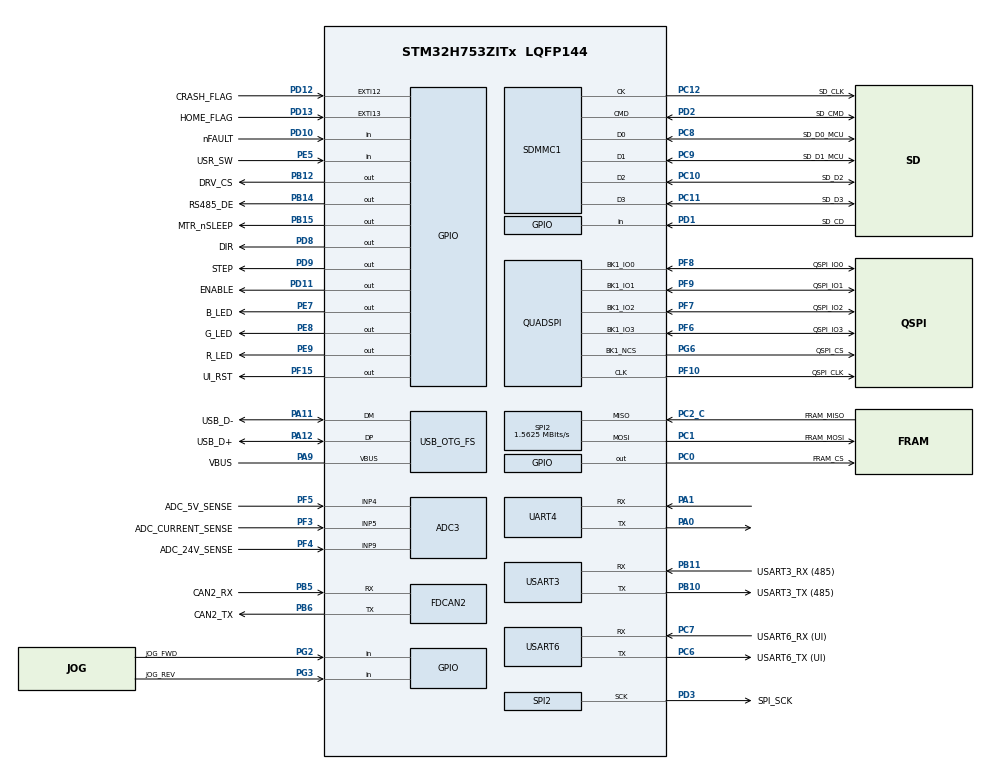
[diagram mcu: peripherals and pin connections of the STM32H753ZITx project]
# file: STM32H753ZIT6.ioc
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ADC3.Channel-0\#ChannelRegularConversion=ADC_CHANNEL_5
ADC3.Channel-1\#ChannelRegularConversion=ADC_CHANNEL_9
ADC3.Channel-2\#ChannelRegularConversion=ADC_CHANNEL_4
ADC3.NbrOfConversion=3
ADC3.NbrOfConversionFlag=1
ADC3.OffsetNumber-0\#ChannelRegularConversion=ADC_OFFSET_NONE
ADC3.OffsetNumber-1\#ChannelRegularConversion=ADC_OFFSET_NONE
ADC3.OffsetNumber-2\#ChannelRegularConversion=ADC_OFFSET_NONE
ADC3.OffsetSignedSaturation-0\#ChannelRegularConversion=DISABLE
ADC3.OffsetSignedSaturation-1\#ChannelRegularConversion=DISABLE
ADC3.OffsetSignedSaturation-2\#ChannelRegularConversion=DISABLE
ADC3.Rank-0\#ChannelRegularConversion=1
ADC3.Rank-1\#ChannelRegularConversion=2
ADC3.Rank-2\#ChannelRegularConversion=3
ADC3.SamplingTime-0\#ChannelRegularConversion=ADC_SAMPLETIME_810CYCLES_5
ADC3.SamplingTime-1\#ChannelRegularConversion=ADC_SAMPLETIME_810CYCLES_5
ADC3.SamplingTime-2\#ChannelRegularConversion=ADC_SAMPLETIME_810CYCLES_5
CORTEX_M7.default_mode_Activation=1
FDCAN2.AutoRetransmission=ENABLE
FDCAN2.CalculateBaudRateNominal=500000
FDCAN2.CalculateTimeBitNominal=2000
FDCAN2.CalculateTimeQuantumNominal=100.0
FDCAN2.NominalPrescaler=5
FDCAN2.NominalTimeSeg1=15
FDCAN2.NominalTimeSeg2=4
FDCAN2.RxFifo0ElmtsNbr=3
FDCAN2.StdFiltersNbr=1
FDCAN2.TxEventsNbr=3
FDCAN2.TxFifoQueueElmtsNbr=3
Mcu.Family=STM32H7
Mcu.Name=STM32H753ZITx
Mcu.Package=LQFP144
NVIC.EXTI15_10_IRQn=true\:6\:0\:true\:false\:true\:true\:true\:true
NVIC.OTG_FS_IRQn=true\:5\:0\:true\:false\:true\:true\:true\:true
NVIC.PriorityGroup=NVIC_PRIORITYGROUP_4
PA0.Mode=Asynchronous
PA0.Signal=UART4_TX
PA1.Mode=Asynchronous
PA1.Signal=UART4_RX
PA11.GPIO_Label=USB_D-
PA11.Mode=Device_Only
PA11.Signal=USB_OTG_FS_DM
PA12.GPIO_Label=USB_D+
PA12.Mode=Device_Only
PA12.Signal=USB_OTG_FS_DP
PA13\ (JTMS/SWDIO).GPIO_Label=DBG_SWDIO
PA13\ (JTMS/SWDIO).Mode=Serial_Wire
PA13\ (JTMS/SWDIO).Signal=DEBUG_JTMS-SWDIO
PA14\ (JTCK/SWCLK).GPIO_Label=DBG_SWCLK
PA14\ (JTCK/SWCLK).Mode=Serial_Wire
PA14\ (JTCK/SWCLK).Signal=DEBUG_JTCK-SWCLK
PA9.GPIO_Label=VBUS
PA9.Mode=Activate_VBUS
PA9.Signal=USB_OTG_FS_VBUS
PB10.GPIO_Label=USART3_TX (485)
PB10.Mode=Asynchronous
PB10.Signal=USART3_TX
PB11.GPIO_Label=USART3_RX (485)
PB11.Mode=Asynchronous
PB11.Signal=USART3_RX
PB12.GPIO_Label=DRV_CS
PB12.PinState=GPIO_PIN_SET
PB12.Signal=GPIO_Output
PB14.GPIO_Label=RS485_DE
PB14.Signal=GPIO_Output
PB15.GPIO_Label=MTR_nSLEEP
PB15.Signal=GPIO_Output
PB3\ (JTDO/TRACESWO).GPIO_Label=DBG_SWO
PB3\ (JTDO/TRACESWO).Signal=DEBUG_JTDO-SWO
PB5.GPIO_Label=CAN2_RX
PB5.Mode=FDCAN_Activate
PB5.Signal=FDCAN2_RX
PB6.GPIO_Label=CAN2_TX
PB6.Mode=FDCAN_Activate
PB6.Signal=FDCAN2_TX
PC0.GPIO_Label=FRAM_CS
PC0.PinState=GPIO_PIN_SET
PC0.Signal=GPIO_Output
PC1.GPIO_Label=FRAM_MOSI
PC1.Mode=Full_Duplex_Master
PC1.Signal=SPI2_MOSI
PC10.GPIO_Label=SD_D2
PC10.Mode=SD_4_bits_Wide_bus
PC10.Signal=SDMMC1_D2
PC11.GPIO_Label=SD_D3
PC11.Mode=SD_4_bits_Wide_bus
PC11.Signal=SDMMC1_D3
PC12.GPIO_Label=SD_CLK
PC12.Mode=SD_4_bits_Wide_bus
PC12.Signal=SDMMC1_CK
PC2_C.GPIO_Label=FRAM_MISO
PC2_C.Mode=Full_Duplex_Master
PC2_C.Signal=SPI2_MISO
PC6.GPIO_Label=USART6_TX (UI)
PC6.Mode=Asynchronous
PC6.Signal=USART6_TX
PC7.GPIO_Label=USART6_RX (UI)
PC7.Mode=Asynchronous
PC7.Signal=USART6_RX
PC8.GPIO_Label=SD_D0_MCU
PC8.Mode=SD_4_bits_Wide_bus
PC8.Signal=SDMMC1_D0
PC9.GPIO_Label=SD_D1_MCU
PC9.Mode=SD_4_bits_Wide_bus
PC9.Signal=SDMMC1_D1
PD1.GPIO_Label=SD_CD
PD1.GPIO_PuPd=GPIO_PULLUP
PD1.Signal=GPIO_Input
PD10.GPIO_Label=nFAULT
PD10.GPIO_PuPd=GPIO_PULLUP
PD10.Signal=GPIO_Input
PD11.GPIO_Label=ENABLE
PD11.GPIO_Speed=GPIO_SPEED_FREQ_LOW
PD11.PinState=GPIO_PIN_RESET
PD11.Signal=GPIO_Output
PD12.GPIO_Label=CRASH_FLAG
PD12.GPIO_ModeDefaultEXTI=GPIO_MODE_IT_FALLING
PD12.GPIO_PuPd=GPIO_PULLUP
PD12.Signal=GPXTI12
PD13.GPIO_Label=HOME_FLAG
PD13.GPIO_ModeDefaultEXTI=GPIO_MODE_IT_FALLING
PD13.GPIO_PuPd=GPIO_PULLUP
PD13.Signal=GPXTI13
PD2.GPIO_Label=SD_CMD
PD2.Mode=SD_4_bits_Wide_bus
PD2.Signal=SDMMC1_CMD
PD3.GPIO_Label=SPI_SCK
PD3.Mode=Full_Duplex_Master
PD3.Signal=SPI2_SCK
PD8.GPIO_Label=DIR
PD8.Signal=GPIO_Output
PD9.GPIO_Label=STEP
PD9.Signal=GPIO_Output
PE5.GPIO_Label=USR_SW
PE5.GPIO_PuPd=GPIO_PULLUP
PE5.Signal=GPIO_Input
PE7.GPIO_Label=B_LED
PE7.Signal=GPIO_Output
PE8.GPIO_Label=G_LED
PE8.Signal=GPIO_Output
PE9.GPIO_Label=R_LED
PE9.Signal=GPIO_Output
PF10.GPIO_Label=QSPI_CLK
PF10.Mode=Single Bank 1
PF10.Signal=QUADSPI_CLK
PF15.GPIO_Label=UI_RST
PF15.Signal=GPIO_Output
PF3.GPIO_Label=ADC_CURRENT_SENSE
PF3.Mode=IN5-Single-Ended
PF3.Signal=ADC3_INP5
PF4.GPIO_Label=ADC_24V_SENSE
PF4.Mode=IN9-Single-Ended
PF4.Signal=ADC3_INP9
PF5.GPIO_Label=ADC_5V_SENSE
PF5.Mode=IN4-Single-Ended
PF5.Signal=ADC3_INP4
PF6.GPIO_Label=QSPI_IO3
PF6.Mode=Single Bank 1
PF6.Signal=QUADSPI_BK1_IO3
PF7.GPIO_Label=QSPI_IO2
PF7.Mode=Single Bank 1
PF7.Signal=QUADSPI_BK1_IO2
PF8.GPIO_Label=QSPI_IO0
PF8.Mode=Single Bank 1
PF8.Signal=QUADSPI_BK1_IO0
PF9.GPIO_Label=QSPI_IO1
PF9.Mode=Single Bank 1
PF9.Signal=QUADSPI_BK1_IO1
PG2.GPIO_Label=JOG_FWD
PG2.GPIO_PuPd=GPIO_PULLUP
PG2.Signal=GPIO_Input
PG3.GPIO_Label=JOG_REV
PG3.GPIO_PuPd=GPIO_PULLUP
PG3.Signal=GPIO_Input
PG6.GPIO_Label=QSPI_CS
PG6.Mode=Single Bank 1
PG6.Signal=QUADSPI_BK1_NCS
PH0-OSC_IN\ (PH0).GPIO_Label=HSE_IN
PH0-OSC_IN\ (PH0).Mode=HSE-External-Oscillator
PH0-OSC_IN\ (PH0).Signal=RCC_OSC_IN
PH1-OSC_OUT\ (PH1).GPIO_Label=HSE_OUT
PH1-OSC_OUT\ (PH1).Mode=HSE-External-Oscillator
PH1-OSC_OUT\ (PH1).Signal=RCC_OSC_OUT
ProjectManager.HeapSize=0x200
ProjectManager.StackSize=0x400
ProjectManager.TargetToolchain=STM32CubeIDE
RCC.ADCFreq_Value=75000000
RCC.APB1Freq_Value=32000000
RCC.APB2Freq_Value=32000000
RCC.APB3Freq_Value=64000000
RCC.APB4Freq_Value=64000000
RCC.CortexFreq_Value=64000000
RCC.D2PPRE1=RCC_APB1_DIV2
RCC.D2PPRE2=RCC_APB2_DIV2
RCC.DIVM1=2
RCC.DIVM2=2
RCC.DIVN1=12
RCC.DIVN2=12
RCC.DIVQ1=3
RCC.HCLKFreq_Value=64000000
RCC.PLL2FRACN=0
RCC.PLL3FRACN=0
RCC.PLLFRACN=0
RCC.SYSCLKFreq_VALUE=64000000
RCC.USBFreq_Value=50000000
SPI2.BaudRatePrescaler=SPI_BAUDRATEPRESCALER_32
SPI2.CalculateBaudRate=1.5625 MBits/s
SPI2.DataSize=SPI_DATASIZE_8BIT
SPI2.Direction=SPI_DIRECTION_2LINES
SPI2.Mode=SPI_MODE_MASTER
SPI2.VirtualType=VM_MASTER
USART3.VirtualMode-Asynchronous=VM_ASYNC
USART6.VirtualMode-Asynchronous=VM_ASYNC
USB_OTG_FS.VirtualMode=Device_Only
VP_MEMORYMAP_VS_MEMORYMAP.Mode=CurAppReg
board=custom

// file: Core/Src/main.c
/* USER CODE BEGIN Header */
/**
  ******************************************************************************
  * @file           : main.c
  * @brief          : Main program body
  ******************************************************************************
  * @attention
  *
  * Copyright (c) 2026 STMicroelectronics.
  * All rights reserved.
  *
  * This software is licensed under terms that can be found in the LICENSE file
  * in the root directory of this software component.
  * If no LICENSE file comes with this software, it is provided AS-IS.
  *
  ******************************************************************************
  */
/* USER CODE END Header */
#include "main.h"

ADC_HandleTypeDef hadc3;

FDCAN_HandleTypeDef hfdcan2;

QSPI_HandleTypeDef hqspi;

SD_HandleTypeDef hsd1;

SPI_HandleTypeDef hspi2;

UART_HandleTypeDef huart4;
UART_HandleTypeDef huart3;
UART_HandleTypeDef huart6;

PCD_HandleTypeDef hpcd_USB_OTG_FS;

void SystemClock_Config(void);
static void MPU_Config(void);
static void MX_GPIO_Init(void);
static void MX_UART4_Init(void);
static void MX_FDCAN2_Init(void);
static void MX_QUADSPI_Init(void);
static void MX_SDMMC1_SD_Init(void);
static void MX_SPI2_Init(void);
static void MX_USART3_UART_Init(void);
static void MX_USB_OTG_FS_PCD_Init(void);
static void MX_ADC3_Init(void);
static void MX_USART6_UART_Init(void);

int main(void)
{

  /* MPU Configuration--------------------------------------------------------*/
  MPU_Config();

  /* MCU Configuration--------------------------------------------------------*/

  /* Reset of all peripherals, Initializes the Flash interface and the Systick. */
  HAL_Init();

  /* Configure the system clock */
  SystemClock_Config();

  /* Initialize all configured peripherals */
  MX_GPIO_Init();
  MX_UART4_Init();
  MX_FDCAN2_Init();
  MX_QUADSPI_Init();
  MX_SDMMC1_SD_Init();
  MX_SPI2_Init();
  MX_USART3_UART_Init();
  MX_USB_OTG_FS_PCD_Init();
  MX_ADC3_Init();
  MX_USART6_UART_Init();
  /* USER CODE BEGIN 2 */
  HAL_GPIO_WritePin(MTR_nSLEEP_GPIO_Port, MTR_nSLEEP_Pin, GPIO_PIN_RESET);
  HAL_GPIO_WritePin(ENABLE_GPIO_Port, ENABLE_Pin, GPIO_PIN_RESET);
  HAL_GPIO_WritePin(RS485_DE_GPIO_Port, RS485_DE_Pin, GPIO_PIN_RESET);

  const char boot_msg[] = "Brain_Board boot\r\n";
  HAL_UART_Transmit(&huart4, (uint8_t *)boot_msg, sizeof(boot_msg) - 1, HAL_MAX_DELAY);
  /* USER CODE END 2 */

  /* Infinite loop */
  /* USER CODE BEGIN WHILE */
  while (1)
  {
	  HAL_GPIO_TogglePin(G_LED_GPIO_Port, G_LED_Pin);
	  HAL_Delay(500);

    /* USER CODE END WHILE */

  }
}

void SystemClock_Config(void)
{
  RCC_OscInitTypeDef RCC_OscInitStruct = {0};
  RCC_ClkInitTypeDef RCC_ClkInitStruct = {0};

  /** Supply configuration update enable
  */
  HAL_PWREx_ConfigSupply(PWR_LDO_SUPPLY);

  /** Configure the main internal regulator output voltage
  */
  __HAL_PWR_VOLTAGESCALING_CONFIG(PWR_REGULATOR_VOLTAGE_SCALE3);

  while(!__HAL_PWR_GET_FLAG(PWR_FLAG_VOSRDY)) {}

  /** Initializes the RCC Oscillators according to the specified parameters
  * in the RCC_OscInitTypeDef structure.
  */
  RCC_OscInitStruct.OscillatorType = RCC_OSCILLATORTYPE_HSI|RCC_OSCILLATORTYPE_HSE;
  RCC_OscInitStruct.HSEState = RCC_HSE_ON;
  RCC_OscInitStruct.HSIState = RCC_HSI_DIV1;
  RCC_OscInitStruct.HSICalibrationValue = RCC_HSICALIBRATION_DEFAULT;
  RCC_OscInitStruct.PLL.PLLState = RCC_PLL_ON;
  RCC_OscInitStruct.PLL.PLLSource = RCC_PLLSOURCE_HSE;
  RCC_OscInitStruct.PLL.PLLM = 2;
  RCC_OscInitStruct.PLL.PLLN = 12;
  RCC_OscInitStruct.PLL.PLLP = 2;
  RCC_OscInitStruct.PLL.PLLQ = 3;
  RCC_OscInitStruct.PLL.PLLR = 2;
  RCC_OscInitStruct.PLL.PLLRGE = RCC_PLL1VCIRANGE_3;
  RCC_OscInitStruct.PLL.PLLVCOSEL = RCC_PLL1VCOMEDIUM;
  RCC_OscInitStruct.PLL.PLLFRACN = 0;
  if (HAL_RCC_OscConfig(&RCC_OscInitStruct) != HAL_OK)
  {
    Error_Handler();
  }

  /** Initializes the CPU, AHB and APB buses clocks
  */
  RCC_ClkInitStruct.ClockType = RCC_CLOCKTYPE_HCLK|RCC_CLOCKTYPE_SYSCLK
                              |RCC_CLOCKTYPE_PCLK1|RCC_CLOCKTYPE_PCLK2
                              |RCC_CLOCKTYPE_D3PCLK1|RCC_CLOCKTYPE_D1PCLK1;
  RCC_ClkInitStruct.SYSCLKSource = RCC_SYSCLKSOURCE_HSI;
  RCC_ClkInitStruct.SYSCLKDivider = RCC_SYSCLK_DIV1;
  RCC_ClkInitStruct.AHBCLKDivider = RCC_HCLK_DIV1;
  RCC_ClkInitStruct.APB3CLKDivider = RCC_APB3_DIV1;
  RCC_ClkInitStruct.APB1CLKDivider = RCC_APB1_DIV2;
  RCC_ClkInitStruct.APB2CLKDivider = RCC_APB2_DIV2;
  RCC_ClkInitStruct.APB4CLKDivider = RCC_APB4_DIV1;

  if (HAL_RCC_ClockConfig(&RCC_ClkInitStruct, FLASH_LATENCY_1) != HAL_OK)
  {
    Error_Handler();
  }
}

static void MX_ADC3_Init(void)
{

  ADC_ChannelConfTypeDef sConfig = {0};

  /** Common config
  */
  hadc3.Instance = ADC3;
  hadc3.Init.Resolution = ADC_RESOLUTION_16B;
  hadc3.Init.ScanConvMode = ADC_SCAN_ENABLE;
  hadc3.Init.EOCSelection = ADC_EOC_SINGLE_CONV;
  hadc3.Init.LowPowerAutoWait = DISABLE;
  hadc3.Init.ContinuousConvMode = DISABLE;
  hadc3.Init.NbrOfConversion = 3;
  hadc3.Init.DiscontinuousConvMode = DISABLE;
  hadc3.Init.ExternalTrigConv = ADC_SOFTWARE_START;
  hadc3.Init.ExternalTrigConvEdge = ADC_EXTERNALTRIGCONVEDGE_NONE;
  hadc3.Init.ConversionDataManagement = ADC_CONVERSIONDATA_DR;
  hadc3.Init.Overrun = ADC_OVR_DATA_PRESERVED;
  hadc3.Init.LeftBitShift = ADC_LEFTBITSHIFT_NONE;
  hadc3.Init.OversamplingMode = DISABLE;
  hadc3.Init.Oversampling.Ratio = 1;
  if (HAL_ADC_Init(&hadc3) != HAL_OK)
  {
    Error_Handler();
  }

  /** Configure Regular Channel
  */
  sConfig.Channel = ADC_CHANNEL_5;
  sConfig.Rank = ADC_REGULAR_RANK_1;
  sConfig.SamplingTime = ADC_SAMPLETIME_810CYCLES_5;
  sConfig.SingleDiff = ADC_SINGLE_ENDED;
  sConfig.OffsetNumber = ADC_OFFSET_NONE;
  sConfig.Offset = 0;
  sConfig.OffsetSignedSaturation = DISABLE;
  if (HAL_ADC_ConfigChannel(&hadc3, &sConfig) != HAL_OK)
  {
    Error_Handler();
  }

  /** Configure Regular Channel
  */
  sConfig.Channel = ADC_CHANNEL_9;
  sConfig.Rank = ADC_REGULAR_RANK_2;
  if (HAL_ADC_ConfigChannel(&hadc3, &sConfig) != HAL_OK)
  {
    Error_Handler();
  }

  /** Configure Regular Channel
  */
  sConfig.Channel = ADC_CHANNEL_4;
  sConfig.Rank = ADC_REGULAR_RANK_3;
  if (HAL_ADC_ConfigChannel(&hadc3, &sConfig) != HAL_OK)
  {
    Error_Handler();
  }

}

static void MX_FDCAN2_Init(void)
{

  hfdcan2.Instance = FDCAN2;
  hfdcan2.Init.FrameFormat = FDCAN_FRAME_CLASSIC;
  hfdcan2.Init.Mode = FDCAN_MODE_NORMAL;
  hfdcan2.Init.AutoRetransmission = ENABLE;
  hfdcan2.Init.TransmitPause = DISABLE;
  hfdcan2.Init.ProtocolException = DISABLE;
  hfdcan2.Init.NominalPrescaler = 5;
  hfdcan2.Init.NominalSyncJumpWidth = 1;
  hfdcan2.Init.NominalTimeSeg1 = 15;
  hfdcan2.Init.NominalTimeSeg2 = 4;
  hfdcan2.Init.DataPrescaler = 1;
  hfdcan2.Init.DataSyncJumpWidth = 1;
  hfdcan2.Init.DataTimeSeg1 = 1;
  hfdcan2.Init.DataTimeSeg2 = 1;
  hfdcan2.Init.MessageRAMOffset = 0;
  hfdcan2.Init.StdFiltersNbr = 1;
  hfdcan2.Init.ExtFiltersNbr = 0;
  hfdcan2.Init.RxFifo0ElmtsNbr = 3;
  hfdcan2.Init.RxFifo0ElmtSize = FDCAN_DATA_BYTES_8;
  hfdcan2.Init.RxFifo1ElmtsNbr = 0;
  hfdcan2.Init.RxFifo1ElmtSize = FDCAN_DATA_BYTES_8;
  hfdcan2.Init.RxBuffersNbr = 0;
  hfdcan2.Init.RxBufferSize = FDCAN_DATA_BYTES_8;
  hfdcan2.Init.TxEventsNbr = 3;
  hfdcan2.Init.TxBuffersNbr = 0;
  hfdcan2.Init.TxFifoQueueElmtsNbr = 3;
  hfdcan2.Init.TxFifoQueueMode = FDCAN_TX_FIFO_OPERATION;
  hfdcan2.Init.TxElmtSize = FDCAN_DATA_BYTES_8;
  if (HAL_FDCAN_Init(&hfdcan2) != HAL_OK)
  {
    Error_Handler();
  }

}

static void MX_QUADSPI_Init(void)
{

  /* QUADSPI parameter configuration*/
  hqspi.Instance = QUADSPI;
  hqspi.Init.ClockPrescaler = 255;
  hqspi.Init.FifoThreshold = 1;
  hqspi.Init.SampleShifting = QSPI_SAMPLE_SHIFTING_NONE;
  hqspi.Init.FlashSize = 1;
  hqspi.Init.ChipSelectHighTime = QSPI_CS_HIGH_TIME_1_CYCLE;
  hqspi.Init.ClockMode = QSPI_CLOCK_MODE_0;
  hqspi.Init.FlashID = QSPI_FLASH_ID_1;
  hqspi.Init.DualFlash = QSPI_DUALFLASH_DISABLE;
  if (HAL_QSPI_Init(&hqspi) != HAL_OK)
  {
    Error_Handler();
  }

}

static void MX_SDMMC1_SD_Init(void)
{

  hsd1.Instance = SDMMC1;
  hsd1.Init.ClockEdge = SDMMC_CLOCK_EDGE_RISING;
  hsd1.Init.ClockPowerSave = SDMMC_CLOCK_POWER_SAVE_DISABLE;
  hsd1.Init.BusWide = SDMMC_BUS_WIDE_4B;
  hsd1.Init.HardwareFlowControl = SDMMC_HARDWARE_FLOW_CONTROL_DISABLE;
  hsd1.Init.ClockDiv = 0;
  if (HAL_SD_Init(&hsd1) != HAL_OK)
  {
    Error_Handler();
  }

}

static void MX_SPI2_Init(void)
{

  /* SPI2 parameter configuration*/
  hspi2.Instance = SPI2;
  hspi2.Init.Mode = SPI_MODE_MASTER;
  hspi2.Init.Direction = SPI_DIRECTION_2LINES;
  hspi2.Init.DataSize = SPI_DATASIZE_8BIT;
  hspi2.Init.CLKPolarity = SPI_POLARITY_LOW;
  hspi2.Init.CLKPhase = SPI_PHASE_1EDGE;
  hspi2.Init.NSS = SPI_NSS_SOFT;
  hspi2.Init.BaudRatePrescaler = SPI_BAUDRATEPRESCALER_32;
  hspi2.Init.FirstBit = SPI_FIRSTBIT_MSB;
  hspi2.Init.TIMode = SPI_TIMODE_DISABLE;
  hspi2.Init.CRCCalculation = SPI_CRCCALCULATION_DISABLE;
  hspi2.Init.CRCPolynomial = 0x0;
  hspi2.Init.NSSPMode = SPI_NSS_PULSE_ENABLE;
  hspi2.Init.NSSPolarity = SPI_NSS_POLARITY_LOW;
  hspi2.Init.FifoThreshold = SPI_FIFO_THRESHOLD_01DATA;
  hspi2.Init.TxCRCInitializationPattern = SPI_CRC_INITIALIZATION_ALL_ZERO_PATTERN;
  hspi2.Init.RxCRCInitializationPattern = SPI_CRC_INITIALIZATION_ALL_ZERO_PATTERN;
  hspi2.Init.MasterSSIdleness = SPI_MASTER_SS_IDLENESS_00CYCLE;
  hspi2.Init.MasterInterDataIdleness = SPI_MASTER_INTERDATA_IDLENESS_00CYCLE;
  hspi2.Init.MasterReceiverAutoSusp = SPI_MASTER_RX_AUTOSUSP_DISABLE;
  hspi2.Init.MasterKeepIOState = SPI_MASTER_KEEP_IO_STATE_DISABLE;
  hspi2.Init.IOSwap = SPI_IO_SWAP_DISABLE;
  if (HAL_SPI_Init(&hspi2) != HAL_OK)
  {
    Error_Handler();
  }

}

static void MX_UART4_Init(void)
{

  huart4.Instance = UART4;
  huart4.Init.BaudRate = 115200;
  huart4.Init.WordLength = UART_WORDLENGTH_8B;
  huart4.Init.StopBits = UART_STOPBITS_1;
  huart4.Init.Parity = UART_PARITY_NONE;
  huart4.Init.Mode = UART_MODE_TX_RX;
  huart4.Init.HwFlowCtl = UART_HWCONTROL_NONE;
  huart4.Init.OverSampling = UART_OVERSAMPLING_16;
  huart4.Init.OneBitSampling = UART_ONE_BIT_SAMPLE_DISABLE;
  huart4.Init.ClockPrescaler = UART_PRESCALER_DIV1;
  huart4.AdvancedInit.AdvFeatureInit = UART_ADVFEATURE_NO_INIT;
  if (HAL_UART_Init(&huart4) != HAL_OK)
  {
    Error_Handler();
  }
  if (HAL_UARTEx_SetTxFifoThreshold(&huart4, UART_TXFIFO_THRESHOLD_1_8) != HAL_OK)
  {
    Error_Handler();
  }
  if (HAL_UARTEx_SetRxFifoThreshold(&huart4, UART_RXFIFO_THRESHOLD_1_8) != HAL_OK)
  {
    Error_Handler();
  }
  if (HAL_UARTEx_DisableFifoMode(&huart4) != HAL_OK)
  {
    Error_Handler();
  }

}

static void MX_USART3_UART_Init(void)
{

  huart3.Instance = USART3;
  huart3.Init.BaudRate = 115200;
  huart3.Init.WordLength = UART_WORDLENGTH_8B;
  huart3.Init.StopBits = UART_STOPBITS_1;
  huart3.Init.Parity = UART_PARITY_NONE;
  huart3.Init.Mode = UART_MODE_TX_RX;
  huart3.Init.HwFlowCtl = UART_HWCONTROL_NONE;
  huart3.Init.OverSampling = UART_OVERSAMPLING_16;
  huart3.Init.OneBitSampling = UART_ONE_BIT_SAMPLE_DISABLE;
  huart3.Init.ClockPrescaler = UART_PRESCALER_DIV1;
  huart3.AdvancedInit.AdvFeatureInit = UART_ADVFEATURE_NO_INIT;
  if (HAL_UART_Init(&huart3) != HAL_OK)
  {
    Error_Handler();
  }
  if (HAL_UARTEx_SetTxFifoThreshold(&huart3, UART_TXFIFO_THRESHOLD_1_8) != HAL_OK)
  {
    Error_Handler();
  }
  if (HAL_UARTEx_SetRxFifoThreshold(&huart3, UART_RXFIFO_THRESHOLD_1_8) != HAL_OK)
  {
    Error_Handler();
  }
  if (HAL_UARTEx_DisableFifoMode(&huart3) != HAL_OK)
  {
    Error_Handler();
  }

}

static void MX_USART6_UART_Init(void)
{

  huart6.Instance = USART6;
  huart6.Init.BaudRate = 115200;
  huart6.Init.WordLength = UART_WORDLENGTH_8B;
  huart6.Init.StopBits = UART_STOPBITS_1;
  huart6.Init.Parity = UART_PARITY_NONE;
  huart6.Init.Mode = UART_MODE_TX_RX;
  huart6.Init.HwFlowCtl = UART_HWCONTROL_NONE;
  huart6.Init.OverSampling = UART_OVERSAMPLING_16;
  huart6.Init.OneBitSampling = UART_ONE_BIT_SAMPLE_DISABLE;
  huart6.Init.ClockPrescaler = UART_PRESCALER_DIV1;
  huart6.AdvancedInit.AdvFeatureInit = UART_ADVFEATURE_NO_INIT;
  if (HAL_UART_Init(&huart6) != HAL_OK)
  {
    Error_Handler();
  }
  if (HAL_UARTEx_SetTxFifoThreshold(&huart6, UART_TXFIFO_THRESHOLD_1_8) != HAL_OK)
  {
    Error_Handler();
  }
  if (HAL_UARTEx_SetRxFifoThreshold(&huart6, UART_RXFIFO_THRESHOLD_1_8) != HAL_OK)
  {
    Error_Handler();
  }
  if (HAL_UARTEx_DisableFifoMode(&huart6) != HAL_OK)
  {
    Error_Handler();
  }

}

static void MX_USB_OTG_FS_PCD_Init(void)
{

  hpcd_USB_OTG_FS.Instance = USB_OTG_FS;
  hpcd_USB_OTG_FS.Init.dev_endpoints = 9;
  hpcd_USB_OTG_FS.Init.speed = PCD_SPEED_FULL;
  hpcd_USB_OTG_FS.Init.dma_enable = DISABLE;
  hpcd_USB_OTG_FS.Init.phy_itface = PCD_PHY_EMBEDDED;
  hpcd_USB_OTG_FS.Init.Sof_enable = DISABLE;
  hpcd_USB_OTG_FS.Init.low_power_enable = DISABLE;
  hpcd_USB_OTG_FS.Init.lpm_enable = DISABLE;
  hpcd_USB_OTG_FS.Init.battery_charging_enable = ENABLE;
  hpcd_USB_OTG_FS.Init.vbus_sensing_enable = ENABLE;
  hpcd_USB_OTG_FS.Init.use_dedicated_ep1 = DISABLE;
  if (HAL_PCD_Init(&hpcd_USB_OTG_FS) != HAL_OK)
  {
    Error_Handler();
  }

}

static void MX_GPIO_Init(void)
{
  GPIO_InitTypeDef GPIO_InitStruct = {0};

  /* GPIO Ports Clock Enable */
  __HAL_RCC_GPIOE_CLK_ENABLE();
  __HAL_RCC_GPIOF_CLK_ENABLE();
  __HAL_RCC_GPIOH_CLK_ENABLE();
  __HAL_RCC_GPIOC_CLK_ENABLE();
  __HAL_RCC_GPIOA_CLK_ENABLE();
  __HAL_RCC_GPIOB_CLK_ENABLE();
  __HAL_RCC_GPIOD_CLK_ENABLE();
  __HAL_RCC_GPIOG_CLK_ENABLE();

  /*Configure GPIO pin Output Level */
  HAL_GPIO_WritePin(FRAM_CS_GPIO_Port, FRAM_CS_Pin, GPIO_PIN_SET);

  /*Configure GPIO pin Output Level */
  HAL_GPIO_WritePin(UI_RST_GPIO_Port, UI_RST_Pin, GPIO_PIN_RESET);

  /*Configure GPIO pin Output Level */
  HAL_GPIO_WritePin(GPIOE, B_LED_Pin|G_LED_Pin|R_LED_Pin, GPIO_PIN_RESET);

  /*Configure GPIO pin Output Level */
  HAL_GPIO_WritePin(DRV_CS_GPIO_Port, DRV_CS_Pin, GPIO_PIN_SET);

  /*Configure GPIO pin Output Level */
  HAL_GPIO_WritePin(GPIOB, RS485_DE_Pin|MTR_nSLEEP_Pin, GPIO_PIN_RESET);

  /*Configure GPIO pin Output Level */
  HAL_GPIO_WritePin(GPIOD, DIR_Pin|STEP_Pin|ENABLE_Pin, GPIO_PIN_RESET);

  /*Configure GPIO pin : USR_SW_Pin */
  GPIO_InitStruct.Pin = USR_SW_Pin;
  GPIO_InitStruct.Mode = GPIO_MODE_INPUT;
  GPIO_InitStruct.Pull = GPIO_PULLUP;
  HAL_GPIO_Init(USR_SW_GPIO_Port, &GPIO_InitStruct);

  /*Configure GPIO pin : FRAM_CS_Pin */
  GPIO_InitStruct.Pin = FRAM_CS_Pin;
  GPIO_InitStruct.Mode = GPIO_MODE_OUTPUT_PP;
  GPIO_InitStruct.Pull = GPIO_NOPULL;
  GPIO_InitStruct.Speed = GPIO_SPEED_FREQ_LOW;
  HAL_GPIO_Init(FRAM_CS_GPIO_Port, &GPIO_InitStruct);

  /*Configure GPIO pin : UI_RST_Pin */
  GPIO_InitStruct.Pin = UI_RST_Pin;
  GPIO_InitStruct.Mode = GPIO_MODE_OUTPUT_PP;
  GPIO_InitStruct.Pull = GPIO_NOPULL;
  GPIO_InitStruct.Speed = GPIO_SPEED_FREQ_LOW;
  HAL_GPIO_Init(UI_RST_GPIO_Port, &GPIO_InitStruct);

  /*Configure GPIO pins : B_LED_Pin G_LED_Pin R_LED_Pin */
  GPIO_InitStruct.Pin = B_LED_Pin|G_LED_Pin|R_LED_Pin;
  GPIO_InitStruct.Mode = GPIO_MODE_OUTPUT_PP;
  GPIO_InitStruct.Pull = GPIO_NOPULL;
  GPIO_InitStruct.Speed = GPIO_SPEED_FREQ_LOW;
  HAL_GPIO_Init(GPIOE, &GPIO_InitStruct);

  /*Configure GPIO pins : DRV_CS_Pin RS485_DE_Pin MTR_nSLEEP_Pin */
  GPIO_InitStruct.Pin = DRV_CS_Pin|RS485_DE_Pin|MTR_nSLEEP_Pin;
  GPIO_InitStruct.Mode = GPIO_MODE_OUTPUT_PP;
  GPIO_InitStruct.Pull = GPIO_NOPULL;
  GPIO_InitStruct.Speed = GPIO_SPEED_FREQ_LOW;
  HAL_GPIO_Init(GPIOB, &GPIO_InitStruct);

  /*Configure GPIO pins : DIR_Pin STEP_Pin ENABLE_Pin */
  GPIO_InitStruct.Pin = DIR_Pin|STEP_Pin|ENABLE_Pin;
  GPIO_InitStruct.Mode = GPIO_MODE_OUTPUT_PP;
  GPIO_InitStruct.Pull = GPIO_NOPULL;
  GPIO_InitStruct.Speed = GPIO_SPEED_FREQ_LOW;
  HAL_GPIO_Init(GPIOD, &GPIO_InitStruct);

  /*Configure GPIO pins : nFAULT_Pin SD_CD_Pin */
  GPIO_InitStruct.Pin = nFAULT_Pin|SD_CD_Pin;
  GPIO_InitStruct.Mode = GPIO_MODE_INPUT;
  GPIO_InitStruct.Pull = GPIO_PULLUP;
  HAL_GPIO_Init(GPIOD, &GPIO_InitStruct);

  /*Configure GPIO pins : CRASH_FLAG_Pin HOME_FLAG_Pin */
  GPIO_InitStruct.Pin = CRASH_FLAG_Pin|HOME_FLAG_Pin;
  GPIO_InitStruct.Mode = GPIO_MODE_IT_FALLING;
  GPIO_InitStruct.Pull = GPIO_PULLUP;
  HAL_GPIO_Init(GPIOD, &GPIO_InitStruct);

  /*Configure GPIO pins : JOG_FWD_Pin JOG_REV_Pin */
  GPIO_InitStruct.Pin = JOG_FWD_Pin|JOG_REV_Pin;
  GPIO_InitStruct.Mode = GPIO_MODE_INPUT;
  GPIO_InitStruct.Pull = GPIO_PULLUP;
  HAL_GPIO_Init(GPIOG, &GPIO_InitStruct);

  /* EXTI interrupt init*/
  HAL_NVIC_SetPriority(CRASH_FLAG_EXTI_IRQn, 6, 0);
  HAL_NVIC_EnableIRQ(CRASH_FLAG_EXTI_IRQn);

}

 /* MPU Configuration */

void MPU_Config(void)
{
  MPU_Region_InitTypeDef MPU_InitStruct = {0};

  /* Disables the MPU */
  HAL_MPU_Disable();

  /** Initializes and configures the Region and the memory to be protected
  */
  MPU_InitStruct.Enable = MPU_REGION_ENABLE;
  MPU_InitStruct.Number = MPU_REGION_NUMBER0;
  MPU_InitStruct.BaseAddress = 0x0;
  MPU_InitStruct.Size = MPU_REGION_SIZE_4GB;
  MPU_InitStruct.SubRegionDisable = 0x87;
  MPU_InitStruct.TypeExtField = MPU_TEX_LEVEL0;
  MPU_InitStruct.AccessPermission = MPU_REGION_NO_ACCESS;
  MPU_InitStruct.DisableExec = MPU_INSTRUCTION_ACCESS_DISABLE;
  MPU_InitStruct.IsShareable = MPU_ACCESS_SHAREABLE;
  MPU_InitStruct.IsCacheable = MPU_ACCESS_NOT_CACHEABLE;
  MPU_InitStruct.IsBufferable = MPU_ACCESS_NOT_BUFFERABLE;

  HAL_MPU_ConfigRegion(&MPU_InitStruct);
  /* Enables the MPU */
  HAL_MPU_Enable(MPU_PRIVILEGED_DEFAULT);

}

void Error_Handler(void)
{
  __disable_irq();
  while (1)
  {
  }
}
